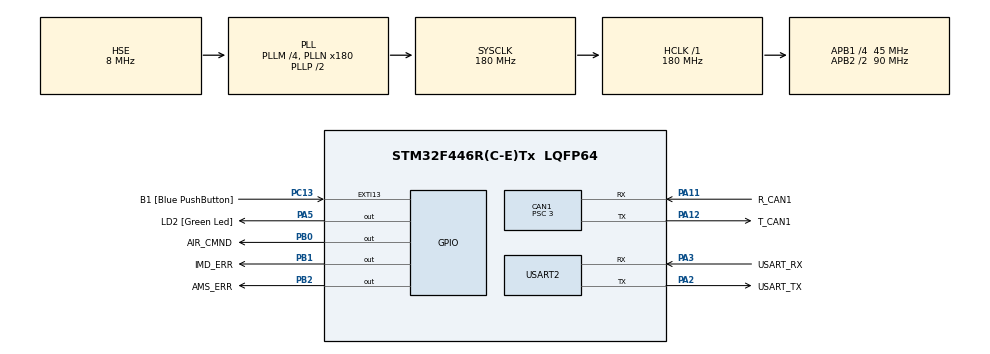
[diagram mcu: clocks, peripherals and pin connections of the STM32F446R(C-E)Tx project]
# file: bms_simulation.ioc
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CAN1.ABOM=ENABLE
CAN1.AWUM=DISABLE
CAN1.BS1=CAN_BS1_12TQ
CAN1.BS2=CAN_BS2_2TQ
CAN1.CalculateBaudRate=1000000
CAN1.CalculateTimeBit=1000
CAN1.CalculateTimeQuantum=66.66666666666666
CAN1.Mode=CAN_MODE_NORMAL
CAN1.NART=DISABLE
CAN1.Prescaler=3
Mcu.Family=STM32F4
Mcu.Name=STM32F446R(C-E)Tx
Mcu.Package=LQFP64
NVIC.CAN1_RX0_IRQn=true\:0\:0\:false\:false\:true\:true\:true\:true
NVIC.CAN1_RX1_IRQn=true\:0\:0\:false\:false\:true\:true\:true\:true
NVIC.CAN1_SCE_IRQn=true\:0\:0\:false\:false\:true\:true\:true\:true
NVIC.PriorityGroup=NVIC_PRIORITYGROUP_0
NVIC.TIM1_UP_TIM10_IRQn=true\:0\:0\:false\:false\:true\:true\:true\:true
NVIC.TIM6_DAC_IRQn=true\:0\:0\:false\:false\:true\:true\:true\:true
NVIC.TIM7_IRQn=true\:0\:0\:false\:false\:true\:true\:true\:true
PA11.GPIO_Label=R_CAN1
PA11.Mode=CAN_Activate
PA11.Signal=CAN1_RX
PA12.GPIO_Label=T_CAN1
PA12.Mode=CAN_Activate
PA12.Signal=CAN1_TX
PA13.GPIO_Label=TMS
PA13.Mode=Serial_Wire
PA13.Signal=SYS_JTMS-SWDIO
PA14.GPIO_Label=TCK
PA14.Mode=Serial_Wire
PA14.Signal=SYS_JTCK-SWCLK
PA2.GPIO_Label=USART_TX
PA2.Mode=Asynchronous
PA2.Signal=USART2_TX
PA3.GPIO_Label=USART_RX
PA3.Mode=Asynchronous
PA3.Signal=USART2_RX
PA5.GPIO_Label=LD2 [Green Led]
PA5.Signal=GPIO_Output
PB0.GPIO_Label=AIR_CMND
PB0.Signal=GPIO_Output
PB1.GPIO_Label=IMD_ERR
PB1.Signal=GPIO_Output
PB2.GPIO_Label=AMS_ERR
PB2.Signal=GPIO_Output
PB3.GPIO_Label=SWO
PB3.Signal=SYS_JTDO-SWO
PC13.GPIO_Label=B1 [Blue PushButton]
PC13.GPIO_ModeDefaultEXTI=GPIO_MODE_IT_FALLING
PC13.Signal=GPXTI13
PC14-OSC32_IN.Signal=RCC_OSC32_IN
PC15-OSC32_OUT.Signal=RCC_OSC32_OUT
PH0-OSC_IN.Mode=HSE-External-Oscillator
PH0-OSC_IN.Signal=RCC_OSC_IN
PH1-OSC_OUT.Mode=HSE-External-Oscillator
PH1-OSC_OUT.Signal=RCC_OSC_OUT
ProjectManager.HeapSize=0x200
ProjectManager.StackSize=0x400
ProjectManager.TargetToolchain=Makefile
RCC.48MHZClocksFreq_Value=84000000
RCC.AHBFreq_Value=180000000
RCC.APB1CLKDivider=RCC_HCLK_DIV4
RCC.APB1Freq_Value=45000000
RCC.APB1TimFreq_Value=90000000
RCC.APB2CLKDivider=RCC_HCLK_DIV2
RCC.APB2Freq_Value=90000000
RCC.APB2TimFreq_Value=180000000
RCC.CortexFreq_Value=180000000
RCC.FLatency-AdvancedSettings=FLASH_LATENCY_5
RCC.HCLKFreq_Value=180000000
RCC.HSE_VALUE=8000000
RCC.HSI_VALUE=16000000
RCC.PLLM=4
RCC.PLLN=180
RCC.PLLSourceVirtual=RCC_PLLSOURCE_HSE
RCC.SYSCLKFreq_VALUE=180000000
RCC.SYSCLKSource=RCC_SYSCLKSOURCE_PLLCLK
RCC.USBFreq_Value=180000000
RCC.VCOOutputFreq_Value=360000000
USART2.VirtualMode=VM_ASYNC
VP_TIM10_VS_ClockSourceINT.Mode=Enable_Timer
VP_TIM2_VS_ClockSourceINT.Mode=Internal
VP_TIM6_VS_ClockSourceINT.Mode=Enable_Timer
VP_TIM7_VS_ClockSourceINT.Mode=Enable_Timer
board=NUCLEO-F446RE

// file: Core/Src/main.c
/* USER CODE BEGIN Header */
/**
  ******************************************************************************
  * @file           : main.c
  * @brief          : Main program body
  ******************************************************************************
  * @attention
  *
  * Copyright (c) 2025 STMicroelectronics.
  * All rights reserved.
  *
  * This software is licensed under terms that can be found in the LICENSE file
  * in the root directory of this software component.
  * If no LICENSE file comes with this software, it is provided AS-IS.
  *
  ******************************************************************************
  */
/* USER CODE END Header */
#include "main.h"
#include "can.h"
#include "tim.h"
#include "usart.h"
#include "gpio.h"

/* USER CODE BEGIN PV */
extern volatile uint8_t can_data_updated;
volatile uint8_t error_code = 0;
uint32_t tick_prev = 0;

/* USER CODE END PV */

void SystemClock_Config(void);

int main(void)
{

  /* MCU Configuration--------------------------------------------------------*/

  /* Reset of all peripherals, Initializes the Flash interface and the Systick. */
  HAL_Init();

  /* Configure the system clock */
  SystemClock_Config();

  /* Initialize all configured peripherals */
  MX_GPIO_Init();
  MX_CAN1_Init();
  MX_USART2_UART_Init();
  MX_TIM2_Init();
  MX_TIM6_Init();
  MX_TIM7_Init();
  MX_TIM10_Init();
  /* USER CODE BEGIN 2 */
  HAL_TIM_Base_Start_IT(&htim2);
  /* USER CODE END 2 */

  /* Infinite loop */
  /* USER CODE BEGIN WHILE */
  volatile uint32_t cnt_10ms  = HAL_GetTick() + 10U;
  while (1)
  {
    /* USER CODE END WHILE */

    /* USER CODE BEGIN 3 */

    //if (HAL_GetTick() >= cnt_10ms) {
      //cnt_10ms = HAL_GetTick() + 10U;

      //BMS_SendMessageRoutine();  //routine called every 10ms
    //}
    if (HAL_GetTick() >= cnt_10ms) {
      cnt_10ms = HAL_GetTick() + 10U;

    }
    BMS_SendMessageRoutine();
    //uint32_t now = HAL_GetTick();

    /*
    if ((now - tick_prev) >= 10) {
      tick_prev = now;
      BMS_SendMessageRoutine(); //send 2 CAN msgs every 10ms
    } */

    if (can_data_updated){ //only trigger the receive routine when new data is received
      can_data_updated=0;
      BMS_ReceiveRoutine();
    }
  }
  /* USER CODE END 3 */
}

void SystemClock_Config(void)
{
  RCC_OscInitTypeDef RCC_OscInitStruct = {0};
  RCC_ClkInitTypeDef RCC_ClkInitStruct = {0};

  /** Configure the main internal regulator output voltage
  */
  __HAL_RCC_PWR_CLK_ENABLE();
  __HAL_PWR_VOLTAGESCALING_CONFIG(PWR_REGULATOR_VOLTAGE_SCALE1);

  /** Initializes the RCC Oscillators according to the specified parameters
  * in the RCC_OscInitTypeDef structure.
  */
  RCC_OscInitStruct.OscillatorType = RCC_OSCILLATORTYPE_HSE;
  RCC_OscInitStruct.HSEState = RCC_HSE_ON;
  RCC_OscInitStruct.PLL.PLLState = RCC_PLL_ON;
  RCC_OscInitStruct.PLL.PLLSource = RCC_PLLSOURCE_HSE;
  RCC_OscInitStruct.PLL.PLLM = 4;
  RCC_OscInitStruct.PLL.PLLN = 180;
  RCC_OscInitStruct.PLL.PLLP = RCC_PLLP_DIV2;
  RCC_OscInitStruct.PLL.PLLQ = 2;
  RCC_OscInitStruct.PLL.PLLR = 2;
  if (HAL_RCC_OscConfig(&RCC_OscInitStruct) != HAL_OK)
  {
    Error_Handler();
  }

  /** Activate the Over-Drive mode
  */
  if (HAL_PWREx_EnableOverDrive() != HAL_OK)
  {
    Error_Handler();
  }

  /** Initializes the CPU, AHB and APB buses clocks
  */
  RCC_ClkInitStruct.ClockType = RCC_CLOCKTYPE_HCLK|RCC_CLOCKTYPE_SYSCLK
                              |RCC_CLOCKTYPE_PCLK1|RCC_CLOCKTYPE_PCLK2;
  RCC_ClkInitStruct.SYSCLKSource = RCC_SYSCLKSOURCE_PLLCLK;
  RCC_ClkInitStruct.AHBCLKDivider = RCC_SYSCLK_DIV1;
  RCC_ClkInitStruct.APB1CLKDivider = RCC_HCLK_DIV4;
  RCC_ClkInitStruct.APB2CLKDivider = RCC_HCLK_DIV2;

  if (HAL_RCC_ClockConfig(&RCC_ClkInitStruct, FLASH_LATENCY_5) != HAL_OK)
  {
    Error_Handler();
  }
}

/* USER CODE BEGIN 4 */
/*
int __io_putchar(int ch)
{
  HAL_UART_Transmit(&huart2, (uint8_t *)&ch, 1, HAL_MAX_DELAY);
  return ch;
}

*/

/* USER CODE END 4 */

void Error_Handler(void)
{
  /* USER CODE BEGIN Error_Handler_Debug */
  /* User can add his own implementation to report the HAL error return state */
 __disable_irq();
  while (1)
  {
    HAL_GPIO_TogglePin(GPIOA, GPIO_PIN_5);
    //HAL_Delay(100);

  }
  /* USER CODE END Error_Handler_Debug */
}
